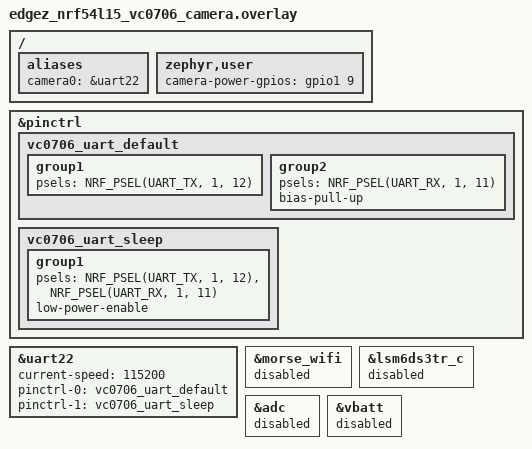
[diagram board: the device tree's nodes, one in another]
#include "edgez_nrf54l15_fgh200m_companion.overlay"

/* The camera replaces the L76K on the FGH200M serial connector. This
 * diagnostic intentionally swaps the inherited GPS TX/RX mapping below.
 * Console output remains on SEGGER RTT.
 */
/ {
	aliases {
		/delete-property/ gps0;
		camera0 = &uart22;
	};

	zephyr,user {
		/delete-property/ gps-wake-gpios;
		camera-power-gpios = <&gpio1 9 GPIO_ACTIVE_HIGH>;
	};
};

/* Diagnostic swapped mapping:
 *   camera RXD <- nRF54L15 P1.12 (UART TX)
 *   camera TXD -> nRF54L15 P1.11 (UART RX)
 */
&pinctrl {
	vc0706_uart_default: vc0706_uart_default {
		group1 {
			psels = <NRF_PSEL(UART_TX, 1, 12)>;
		};

		group2 {
			psels = <NRF_PSEL(UART_RX, 1, 11)>;
			bias-pull-up;
		};
	};

	vc0706_uart_sleep: vc0706_uart_sleep {
		group1 {
			psels = <NRF_PSEL(UART_TX, 1, 12)>,
				<NRF_PSEL(UART_RX, 1, 11)>;
			low-power-enable;
		};
	};
};

&uart22 {
	/* Initialize at a conservative rate, then switch to the camera's
	 * 921600 baud rate with uart_configure() before the first command.
	 */
	current-speed = <115200>;
	pinctrl-0 = <&vc0706_uart_default>;
	pinctrl-1 = <&vc0706_uart_sleep>;
	pinctrl-names = "default", "sleep";
};

&morse_wifi {
	status = "disabled";
};

&lsm6ds3tr_c {
	status = "disabled";
};

&adc {
	status = "disabled";
};

&vbatt {
	status = "disabled";
};
